# M2003 register map
File version: 1.0
Registers are 32-bit, read-write, reset 0x0 unless marked. A register's access mark holds for its fields unless they carry their own. Offsets are from the block's base; [hi:lo] are bit positions; lines under a group give offsets from that group; {n}, {i} and the like mark numbered series; 'fields as' and 'values as' point back to an identical list.

## CLK — CLK Register Map
Base 0x40000200
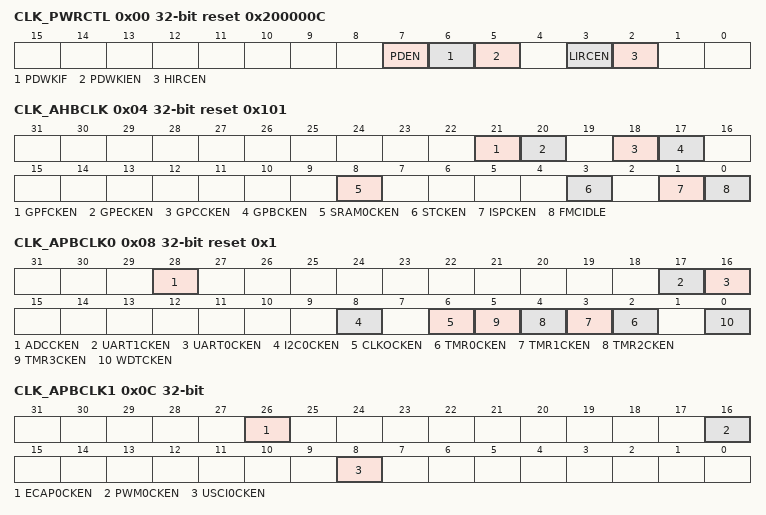
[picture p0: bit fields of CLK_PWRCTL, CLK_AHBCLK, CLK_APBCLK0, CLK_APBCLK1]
0x00 CLK_PWRCTL reset 0x200000C — System Power-down Control Register
  [7] PDEN — System Power-down Enable (Write Protect). When this bit is set to 1, Power-down mode is enabled and the chip keeps active till the CPU sleep mode is also active and then the chip enters Power-down mode. When chip wakes up from Power-down mode, this bit is auto cleared. Users need to set this bit again for next Power-down. In Power-down mode, HIRC and system clock will be disabled and ignored the clock source selection. The clocks of peripheral are not controlled by Power-down mode, if the peripheral clock source is from LIRC. Note: This bit is write protected. Refer to the SYS_REGLCTL register.
    0=Chip operating normally or chip in idle mode because of WFI command; 1=Chip waits CPU sleep command WFI and then enters Power-down mode
  [6] PDWKIF — Power-down Mode Wake-up Interrupt Status. Set by 'Power-down wake-up event', it indicates that resume from Power-down mode' The flag is set if the EINT0~5, GPIO, UART0~1, BOD, WDT, TIMER, I2C0, USCI0 and CLKD wake-up occurred. Note 1: Write 1 to clear the bit to 0. Note 2: This bit works only if PDWKIEN (CLK_PWRCTL[5]) set to 1.
  [5] PDWKIEN — Power-down Mode Wake-up Interrupt Enable Bit (Write Protect). Note 1: The interrupt will occur when both PDWKIF and PDWKIEN are high, after resume from power-down mode. Note 2: This bit is write protected. Refer to the SYS_REGLCTL register.
    0=Power-down mode wake-up interrupt Disabled; 1=Power-down mode wake-up interrupt Enabled
  [3] LIRCEN — LIRC Enable Bit (Write Protect). Note 1: This bit is write protected. Refer to the SYS_REGLCTL register. Note 2: LIRC cannot be disabled and LIRCEN will read as 1 if HCLK clock source is selected from LIRC. Note 3: If CWDTEN(CONFIG0[31,4:3]) is set to 111, LIRC clock can be enabled or disabled by setting LIRCEN(CLK_PWRCTL[3]). If CWDTEN(CONFIG0[31,4:3]) is not set to 111, LIRC cannot be disabled in normal mode. In Power-down mode, LIRC clock is controlled by LIRCEN(CLK_PWRCTL[3]) and CWDTPDEN(CONFIG0[30]) setting.
    0=10 kHz internal low speed RC oscillator (LIRC) Disabled; 1=10 kHz internal low speed RC oscillator (LIRC) Enabled
  [2] HIRCEN — HIRC Enable Bit (Write Protect). Note 1: This bit is write protected. Refer to the SYS_REGLCTL register. Note 2: HIRC cannot be disabled and HIRCEN will read as 1 if HCLK clock source is selected from HIRC (clock source from HIRC).
    0=24 MHz internal high speed RC oscillator (HIRC) Disabled; 1=24 MHz internal high speed RC oscillator (HIRC) Enabled
0x04 CLK_AHBCLK reset 0x101 — AHB Devices Clock Enable Register
  [21] GPFCKEN — GPIOF Clock Enable Bit
    0=GPIOF port clock Disabled; 1=GPIOF port clock Enabled
  [20] GPECKEN — GPIOE Clock Enable Bit
    0=GPIOE port clock Disabled; 1=GPIOE port clock Enabled
  [18] GPCCKEN — GPIOC Clock Enable Bit
    0=GPIOC port clock Disabled; 1=GPIOC port clock Enabled
  [17] GPBCKEN — GPIOB Clock Enable Bit
    0=GPIOB port clock Disabled; 1=GPIOB port clock Enabled
  [8] SRAM0CKEN — SRAM Bank0 Controller Clock Enable Bit
    0=SRAM bank0 clock Disabled; 1=SRAM bank0 clock Enabled
  [3] STCKEN — System Tick Clock Enable Bit
    0=External System tick clock Disabled; 1=External System tick clock Enabled
  [1] ISPCKEN — Flash ISP Controller Clock Enable Bit
    0=Flash ISP peripheral clock Disabled; 1=Flash ISP peripheral clock Enabled
  [0] FMCIDLE — Flash Memory Controller Clock Enable Bit in IDLE Mode
    0=FMC clock Disabled when chip is under IDLE mode; 1=FMC clock Enabled when chip is under IDLE mode
0x08 CLK_APBCLK0 reset 0x1 — APB Devices Clock Enable Register 0
  [28] ADCCKEN — Analog-digital-converter Clock Enable Bit
    0=ADC clock Disabled; 1=ADC clock Enabled
  [17] UART1CKEN — UART1 Clock Enable Bit
    0=UART1 clock Disabled; 1=UART1 clock Enabled
  [16] UART0CKEN — UART0 Clock Enable Bit
    0=UART0 clock Disabled; 1=UART0 clock Enabled
  [8] I2C0CKEN — I2C0 Clock Enable Bit
    0=I2C0 clock Disabled; 1=I2C0 clock Enabled
  [6] CLKOCKEN — CLKO Clock Enable Bit
    0=CLKO clock Disabled; 1=CLKO clock Enabled
  [n+2] TMR{n}CKEN (n=0..3) — Timer{n} Clock Enable Bit
    0=Timer{n} clock Disabled; 1=Timer{n} clock Enabled
  [0] WDTCKEN — Watchdog Timer Clock Enable Bit (Write Protect). Note: This bit is write protected. Refer to the SYS_REGLCTL register.
    0=Watchdog timer and Windows watchdog timer clock Disabled; 1=Watchdog timer and Windows watchdog timer clock Enabled
0x0C CLK_APBCLK1 — APB Devices Clock Enable Register 1
  [26] ECAP0CKEN — ECAP0 Clock Enable Bit
    0=ECAP0 clock Disabled; 1=ECAP0 clock Enabled
  [16] PWM0CKEN — PWM0 Clock Enable Bit
    0=PWM0 clock Disabled; 1=PWM0 clock Enabled
  [8] USCI0CKEN — USCI0 Clock Enable Bit
    0=USCI0 clock Disabled; 1=USCI0 clock Enabled
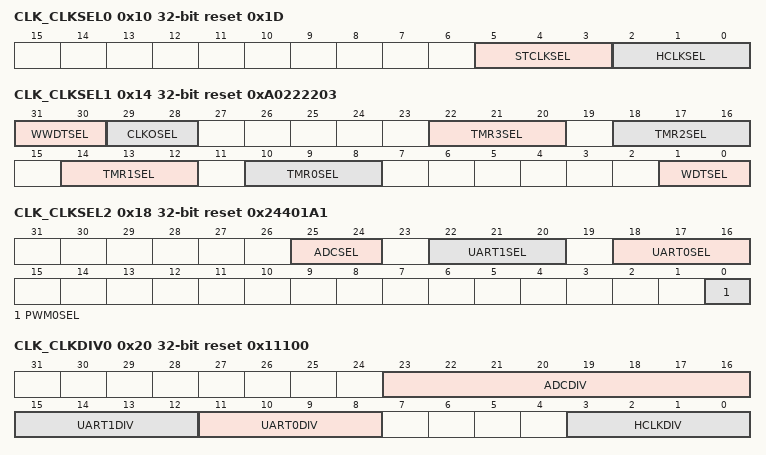
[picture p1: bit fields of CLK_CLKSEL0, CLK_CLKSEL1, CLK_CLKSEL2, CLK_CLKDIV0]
0x10 CLK_CLKSEL0 reset 0x1D — Clock Source Select Register 0
  [5:3] STCLKSEL — SysTick Clock Source Selection (Write Protect). Note 2: These bits are write protected. Refer to the SYS_REGLCTL register.
    3=Clock source from HCLK/2; 4=Clock source from HIRC/2
  [2:0] HCLKSEL — HCLK Clock Source Selection (Write Protect). Before clock switching, the related clock sources (both pre-select and new-select) must be turned on. Note: These bits are write protected. Refer to the SYS_REGLCTL register.
    3=Clock source from LIRC; 4=Clock source from HIRC
0x14 CLK_CLKSEL1 reset 0xA0222203 — Clock Source Select Register 1
  [31:30] WWDTSEL — Window Watchdog Timer Clock Source Selection (Write Protect). Note: These bits are write protected. Refer to the SYS_REGLCTL register.
    2=Clock source from HCLK/2048; 3=Clock source from 10 kHz internal low speed RC oscillator (LIRC)
  [29:28] CLKOSEL — Clock Output Clock Source Selection
    2=Clock source from HCLK; 3=Clock source from 24 MHz internal high speed RC oscillator (HIRC)
  [22:20] TMR3SEL — TIMER3 Clock Source Selection
    2=Clock source from PCLK1; 3=Clock source from external clock TM3 pin; 4=Clock source from 10 kHz internal low speed RC oscillator (LIRC); 5=Clock source from 24 MHz internal high speed RC oscillator (HIRC)
  [18:16] TMR2SEL — TIMER2 Clock Source Selection
    2=Clock source from PCLK1; 3=Clock source from external clock TM2 pin; 4=Clock source from 10 kHz internal low speed RC oscillator (LIRC); 5=Clock source from 24 MHz internal high speed RC oscillator (HIRC)
  [14:12] TMR1SEL — TIMER1 Clock Source Selection
    2=Clock source from PCLK0; 3=Clock source from external clock TM1 pin; 4=Clock source from 10 kHz internal low speed RC oscillator (LIRC); 5=Clock source from 24 MHz internal high speed RC oscillator (HIRC)
  [10:8] TMR0SEL — TIMER0 Clock Source Selection
    2=Clock source from PCLK0; 3=Clock source from external clock TM0 pin; 4=Clock source from 10 kHz internal low speed RC oscillator (LIRC); 5=Clock source from 24 MHz internal high speed RC oscillator (HIRC)
  [1:0] WDTSEL — Watchdog Timer Clock Source Selection (Write Protect). Note: These bits are write protected. Refer to the SYS_REGLCTL register.
    values as WWDTSEL
0x18 CLK_CLKSEL2 reset 0x24401A1 — Clock Source Select Register 2
  [25:24] ADCSEL — ADC Clock Source Selection
    2=Clock source from PCLK2; 3=Clock source from 24 MHz internal high speed RC oscillator (HIRC)
  [22:20] UART1SEL — UART1 Clock Source Selection
    3=Clock source from 24 MHz internal high speed RC oscillator (HIRC); 4=Clock source from PCLK1
  [18:16] UART0SEL — UART0 Clock Source Selection
    3=Clock source from 24 MHz internal high speed RC oscillator (HIRC); 4=Clock source from PCLK0
  [0] PWM0SEL ro — PWM0 Clock Source Selection (Read Only). The peripheral clock source of PWM0 is defined by PWM0SEL.
    1=Clock source from PCLK0
0x20 CLK_CLKDIV0 reset 0x11100 — Clock Divider Number Register 0
  [23:16] ADCDIV — ADC Clock Divide Number From ADC Clock Source
  [15:12] UART1DIV — UART1 Clock Divide Number From UART1 Clock Source
  [11:8] UART0DIV — UART0 Clock Divide Number From UART0 Clock Source
  [3:0] HCLKDIV — HCLK Clock Divide Number From HCLK Clock Source
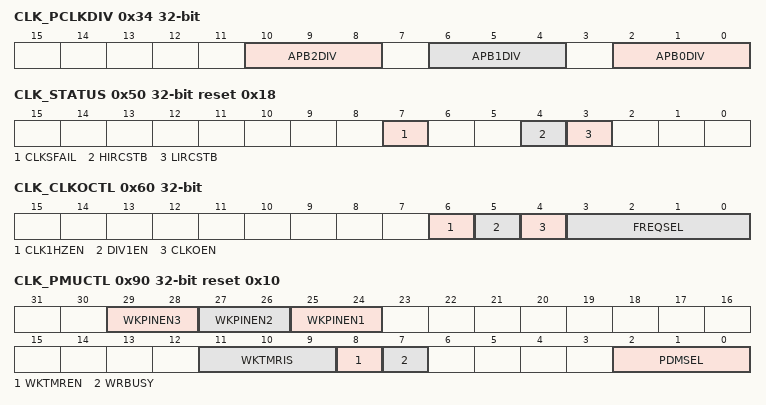
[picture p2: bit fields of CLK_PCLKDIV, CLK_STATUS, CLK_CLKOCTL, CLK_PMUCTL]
0x34 CLK_PCLKDIV — APB Clock Divider Register
  [10:8] APB2DIV — APB2 Clock Divider. APB2 clock can be divided from HCLK.
    0=PCLK2 frequency is HCLK; 1=PCLK2 frequency is 1/2 HCLK; 2=PCLK2 frequency is 1/4 HCLK; 3=PCLK2 frequency is 1/8 HCLK; 4=PCLK2 frequency is 1/16 HCLK; 5=PCLK2 frequency is 1/32 HCLK
  [6:4] APB1DIV — APB1 Clock Divider. APB1 clock can be divided from HCLK.
    0=PCLK1 frequency is HCLK; 1=PCLK1 frequency is 1/2 HCLK; 2=PCLK1 frequency is 1/4 HCLK; 3=PCLK1 frequency is 1/8 HCLK; 4=PCLK1 frequency is 1/16 HCLK; 5=PCLK1 frequency is 1/32 HCLK
  [2:0] APB0DIV — APB0 Clock Divider. APB0 clock can be divided from HCLK.
    0=PCLK0 frequency is HCLK; 1=PCLK0 frequency is 1/2 HCLK; 2=PCLK0 frequency is 1/4 HCLK; 3=PCLK0 frequency is 1/8 HCLK; 4=PCLK0 frequency is 1/16 HCLK; 5=PCLK0 frequency is 1/32 HCLK
0x50 CLK_STATUS ro reset 0x18 — Clock Status Monitor Register
  [7] CLKSFAIL — Clock Switching Fail Flag (Read Only). This bit is updated when software switches system clock source. If switch target clock is stable, this bit will be set to 0. If switch target clock is not stable, this bit will be set to 1. Note: This bit is read only. After selected clock source is stable, hardware will switch system clock to selected clock automatically, and CLKSFAIL will be cleared automatically by hardware.
    0=Clock switching success; 1=Clock switching failure
  [4] HIRCSTB — HIRC Clock Source Stable Flag (Read Only)
    0=24 MHz internal high speed RC oscillator (HIRC) clock is not stable or disabled; 1=24 MHz internal high speed RC oscillator (HIRC) clock is stable and enabled
  [3] LIRCSTB — LIRC Clock Source Stable Flag (Read Only)
    0=10 kHz internal low speed RC oscillator (LIRC) clock is not stable or disabled; 1=10 kHz internal low speed RC oscillator (LIRC) clock is stable and enabled
0x60 CLK_CLKOCTL — Clock Output Control Register
  [6] CLK1HZEN — CLK1HZEN. Note: This bits has to set to 0.
  [5] DIV1EN — Clock Output Divide One Enable Bit
    0=Clock Output will output clock with source frequency divided by FREQSEL; 1=Clock Output will output clock with source frequency
  [4] CLKOEN — Clock Output Enable Bit
    0=Clock Output function Disabled; 1=Clock Output function Enabled
  [3:0] FREQSEL — Clock Output Frequency Selection. The formula of output frequency is. Fin is the input clock frequency. Fout is the frequency of divider output clock. N is the 4-bit value of FREQSEL[3:0].
0x90 CLK_PMUCTL reset 0x10 — Power Manager Control Register
  [29:28] WKPINEN3
  [27:26] WKPINEN2 — Wake-up Pin 3 Enable Bits (Write Protect). This is control register for GPB.12 to wake-up pin. Note: These bits are write protected. Refer to the SYS_REGLCTL register.
    0=Wake-up pin disable at Power-down mode; 1=Wake-up pin rising edge enabled at Power-down mode; 2=Wake-up pin falling edge enabled at Power-down mode; 3=Wake-up pin both edge enabled at Power-down mode
  [25:24] WKPINEN1 — Wake-up Pin 1 Enable Bits (Write Protect). This is control register for GPB.0 to wake-up pin. Note: These bits are write protected. Refer to the SYS_REGLCTL register.
    values as WKPINEN2
  [11:9] WKTMRIS — Wake-up Timer Time-out Interval Select Bits (Write Protect). These bits control wake-up timer time-out interval when chip under Power-down mode. Note: These bits are write protected. Refer to the SYS_REGLCTL register.
    0=Time-out interval is 128 LIRC clocks (12.8ms); 1=Time-out interval is 256 LIRC clocks (25.6ms); 2=Time-out interval is 512 LIRC clocks (51.2ms); 3=Time-out interval is 1024 LIRC clocks (102.4ms); 4=Time-out interval is 4096 LIRC clocks (409.6ms); 5=Time-out interval is 8192 LIRC clocks (819.2ms); 6=Time-out interval is 16384 LIRC clocks (1638.4ms); 7=Time-out interval is 65536 LIRC clocks (6553.6ms)
  [8] WKTMREN — Wake-up Timer Enable Bit (Write Protect). Note: This bit is write protected. Refer to the SYS_REGLCTL register.
    0=Wake-up timer disable at Power-down mode; 1=Wake-up timer enabled at Power-down mode
  [7] WRBUSY ro — Write Busy Flag (Read Only). If CLK_PMUCTL be written, this bit be asserted automatic by hardware, and be de-asserted when write procedure finish.
    0=CLK_PMUCTL write ready; 1=CLK_PMUCTL write ignore
  [2:0] PDMSEL — Power-down Mode Selection (Write Protect). These bits control chip power-down mode grade selection when CPU executes WFI/WFE instruction. Note: These bits are write protected. Refer to the SYS_REGLCTL register.
    0=Power-down mode is selected (PD)
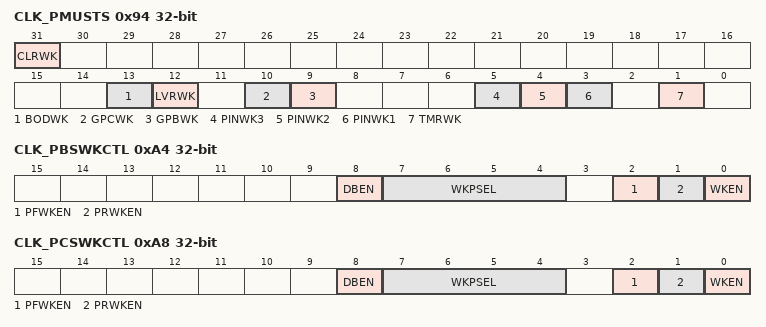
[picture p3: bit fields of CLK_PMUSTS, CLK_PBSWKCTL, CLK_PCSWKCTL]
0x94 CLK_PMUSTS — Power Manager Status Register
  [31] CLRWK — Clear Wake-up Flag. Note: This bit is auto cleared by hardware.
    0=No clear; 1=Clear all of wake-up flag
  [13] BODWK ro — BOD Wake-up Flag (Read Only). This flag indicates that wakeup of device from Power-down mode was requested with a BOD happened..
  [12] LVRWK ro — LVR Wake-up Flag (Read Only). This flag indicates that wakeup of device from Power-down mode was requested with a LVR happened.
  [10] GPCWK ro — GPC Wake-up Flag (Read Only). This flag indicates that wake-up of chip from Power-down mode was requested by a transition of selected one GPC group pins.
  [9] GPBWK ro — GPB Wake-up Flag (Read Only). This flag indicates that wake-up of chip from Power-down mode was requested by a transition of selected one GPB group pins.
  [5] PINWK3 ro — Pin 3 Wake-up Flag (Read Only). This flag indicates that wake-up of chip from Power-down mode was requested by a transition of the Wake-up pin (GPB.12).
  [4] PINWK2 ro — Pin 2 Wake-up Flag (Read Only). This flag indicates that wake-up of chip from Power-down mode was requested by a transition of the Wake-up pin (GPB.2).
  [3] PINWK1 ro — Pin 1 Wake-up Flag (Read Only). This flag indicates that wake-up of chip from Power-down mode was requested by a transition of the Wake-up pin (GPB.0).
  [1] TMRWK ro — Timer Wake-up Flag (Read Only). This flag indicates that wake-up of chip from Power-down mode was requested by wakeup timer time-out.
0x9C CLK_SWKDBCTL — Power-down Wake-up De-bounce Control Register
  [3:0] SWKDBCLKSEL — Power-down Wake-up De-bounce Sampling Cycle Selection. Note: De-bounce counter clock source is the 10kHz internal low speed RC oscillator (LIRC).
    0=Sample wake-up input once per 1 clocks; 1=Sample wake-up input once per 2 clocks; 2=Sample wake-up input once per 4 clocks; 3=Sample wake-up input once per 8 clocks; 4=Sample wake-up input once per 16 clocks; 5=Sample wake-up input once per 32 clocks; 6=Sample wake-up input once per 64 clocks; 7=Sample wake-up input once per 128 clocks; 8=Sample wake-up input once per 256 clocks; 9=Sample wake-up input once per 2*256 clocks; 10=Sample wake-up input once per 4*256 clocks; 11=Sample wake-up input once per 8*256 clocks; 12=Sample wake-up input once per 16*256 clocks; 13=Sample wake-up input once per 32*256 clocks; 14=Sample wake-up input once per 64*256 clocks; 15=Sample wake-up input once per 128*256 clocks
0xA4 CLK_PBSWKCTL — GPB Power-down Wake-up Control Register
  [8] DBEN — GPB Input Signal De-bounce Enable Bit. The DBEN bit is used to enable the de-bounce function for each corresponding I/O. If the input signal pulse width cannot be sampled by continuous two de-bounce sample cycle, the input signal transition is seen as the signal bounce and will not trigger the wakeup.The de-bounce clock source is the 10 kHz internal low speed RC oscillator (LIRC). Note: The de-bounce function is valid only for edge triggered.
    0=power-down wake-up pin De-bounce function Disabled; 1=power-down wake-up pin De-bounce function Enabled
  [7:4] WKPSEL — GPB Standby Power-down Wake-up Pin Select. Others are reserved.
    0=GPB.0 wake-up function Enabled; 1=GPB.1 wake-up function Enabled; 2=GPB.2 wake-up function Enabled; 3=GPB.3 wake-up function Enabled; 4=GPB.4 wake-up function Enabled; 5=GPB.5 wake-up function Enabled; 7=GPB.7 wake-up function Enabled; 8=GPB.8 wake-up function Enabled; 9=GPB.9 wake-up function Enabled; 11=GPB.11 wake-up function Enabled; 12=GPB.12 wake-up function Enabled; 13=GPB.13 wake-up function Enabled; 14=GPB.14 wake-up function Enabled; 15=GPB.15 wake-up function Enabled
  [2] PFWKEN — Pin Falling Edge Wake-up Enable Bit
    0=GPB group pin falling edge wake-up function Disabled; 1=GPB group pin falling edge wake-up function Enabled
  [1] PRWKEN — Pin Rising Edge Wake-up Enable Bit
    0=GPB group pin rising edge wake-up function Disabled; 1=GPB group pin rising edge wake-up function Enabled
  [0] WKEN — Power-down Pin Wake-up Enable Bit
    0=GPB group pin wake-up function Disabled; 1=GPB group pin wake-up function Enabled
0xA8 CLK_PCSWKCTL — GPC Power-down Wake-up Control Register
  [8] DBEN — GPC Input Signal De-bounce Enable Bit. The DBEN bit is used to enable the de-bounce function for each corresponding I/O. If the input signal pulse width cannot be sampled by continuous two de-bounce sample cycle, the input signal transition is seen as the signal bounce and will not trigger the wakeup.The de-bounce clock source is the 10 kHz internal low speed RC oscillator. The de-bounce function is valid only for edge triggered.
    values as CLK_PBSWKCTL.DBEN
  [7:4] WKPSEL — GPC Power-down Wake-up Pin Select. Others are reserved
    14=GPC.14 wake-up function Enabled
  [2] PFWKEN — Pin Falling Edge Wake-up Enable Bit
    0=GPC group pin falling edge wake-up function Disabled; 1=GPC group pin falling edge wake-up function Enabled
  [1] PRWKEN — Pin Rising Edge Wake-up Enable Bit
    0=GPC group pin rising edge wake-up function Disabled; 1=GPC group pin rising edge wake-up function Enabled
  [0] WKEN — Standby Power-down Pin Wake-up Enable Bit
    0=GPC group pin wake-up function Disabled; 1=GPC group pin wake-up function Enabled
0xB0 CLK_IOPDCTL — GPIO Power-down Control Register
  [0] IOHR — GPIO Hold Release. When GPIO enter power-down mode, all I/O status are hold to keep normal operating status. After chip was waked up from power-down mode, the I/O are still keep hold status until user set this bit to release I/O hold status. Note: This bit is auto cleared by hardware.
